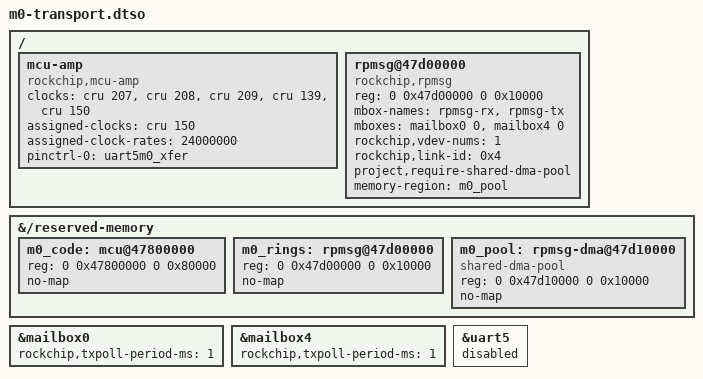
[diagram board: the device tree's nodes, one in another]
/dts-v1/;
/plugin/;
/ {
    fragment@0 { target-path = "/reserved-memory";
        __overlay__ { #address-cells = <2>; #size-cells = <2>;
            m0_code: mcu@47800000 { reg = <0 0x47800000 0 0x80000>; no-map; };
            m0_rings: rpmsg@47d00000 { reg = <0 0x47d00000 0 0x10000>; no-map; };
            m0_pool: rpmsg-dma@47d10000 { compatible = "shared-dma-pool";
                reg = <0 0x47d10000 0 0x10000>; no-map; };
        };
    };
    fragment@1 { target-path = "/";
        __overlay__ { #address-cells = <2>; #size-cells = <2>;
            mcu-amp { compatible = "rockchip,mcu-amp";
                clocks = <&cru 207>, <&cru 208>, <&cru 209>, <&cru 139>, <&cru 150>;
                assigned-clocks = <&cru 150>; assigned-clock-rates = <24000000>;
                pinctrl-names = "default"; pinctrl-0 = <&uart5m0_xfer>;
                status = "okay";
            };
            rpmsg@47d00000 { compatible = "rockchip,rpmsg";
                reg = <0 0x47d00000 0 0x10000>;
                mbox-names = "rpmsg-rx", "rpmsg-tx";
                mboxes = <&mailbox0 0>, <&mailbox4 0>;
                rockchip,vdev-nums = <1>; rockchip,link-id = <0x4>;
                project,require-shared-dma-pool;
                memory-region = <&m0_pool>; status = "okay";
            };
        };
    };
    fragment@2 { target = <&mailbox0>; __overlay__ { rockchip,txpoll-period-ms = <1>; status = "okay"; }; };
    fragment@3 { target = <&mailbox4>; __overlay__ { rockchip,txpoll-period-ms = <1>; status = "okay"; }; };
    fragment@4 { target = <&uart5>; __overlay__ { status = "disabled"; }; };
};
